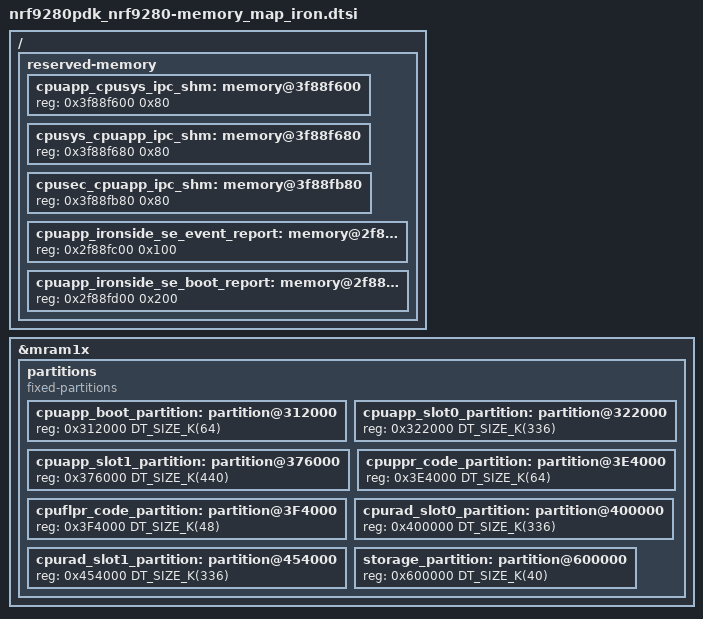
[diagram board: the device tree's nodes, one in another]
/*
 * Copyright (c) 2025 Nordic Semiconductor ASA
 *
 * SPDX-License-Identifier: Apache-2.0
 */

/* This file is to be merged with the original memory_map.dtsi in the future.
 * The following nodes will be replaced:
 */
/delete-node/ &cpuapp_cpusys_ipc_shm;
/delete-node/ &cpusec_cpuapp_ipc_shm;
/delete-node/ &cpusys_cpuapp_ipc_shm;
/delete-node/ &cpuapp_rw_partitions;
/delete-node/ &cpuapp_rx_partitions;
/delete-node/ &cpurad_rx_partitions;

/ {
	reserved-memory {
		/* Workaround for a data cache related issue with SoC1.1, use secure addresses
		 * for cpuapp_cpusys_ipc_shm, cpusys_cpuapp_ipc_shm and cpusec_cpuapp_ipc_shm.
		 */
		cpuapp_cpusys_ipc_shm: memory@3f88f600 {
			reg = <0x3f88f600 0x80>;
		};

		cpusys_cpuapp_ipc_shm: memory@3f88f680 {
			reg = <0x3f88f680 0x80>;
		};

		cpusec_cpuapp_ipc_shm: memory@3f88fb80 {
			reg = <0x3f88fb80 0x80>;
		};

		cpuapp_ironside_se_event_report: memory@2f88fc00 {
			reg = <0x2f88fc00 0x100>;
		};

		cpuapp_ironside_se_boot_report: memory@2f88fd00 {
			reg = <0x2f88fd00 0x200>;
		};
	};
};

&mram1x {
	partitions {
		compatible = "fixed-partitions";
		#address-cells = <1>;
		#size-cells = <1>;

		cpuapp_boot_partition: partition@312000 {
			reg = <0x312000 DT_SIZE_K(64)>;
		};

		cpuapp_slot0_partition: partition@322000 {
			reg = <0x322000 DT_SIZE_K(336)>;
		};

		cpuapp_slot1_partition: partition@376000 {
			reg = <0x376000 DT_SIZE_K(440)>;
		};

		cpuppr_code_partition: partition@3E4000 {
			reg = <0x3E4000 DT_SIZE_K(64)>;
		};

		cpuflpr_code_partition: partition@3F4000 {
			reg = <0x3F4000 DT_SIZE_K(48)>;
		};

		cpurad_slot0_partition: partition@400000 {
			reg = <0x400000 DT_SIZE_K(336)>;
		};

		cpurad_slot1_partition: partition@454000 {
			reg = <0x454000 DT_SIZE_K(336)>;
		};

		storage_partition: partition@600000 {
			reg = <0x600000 DT_SIZE_K(40)>;
		};
	};
};
